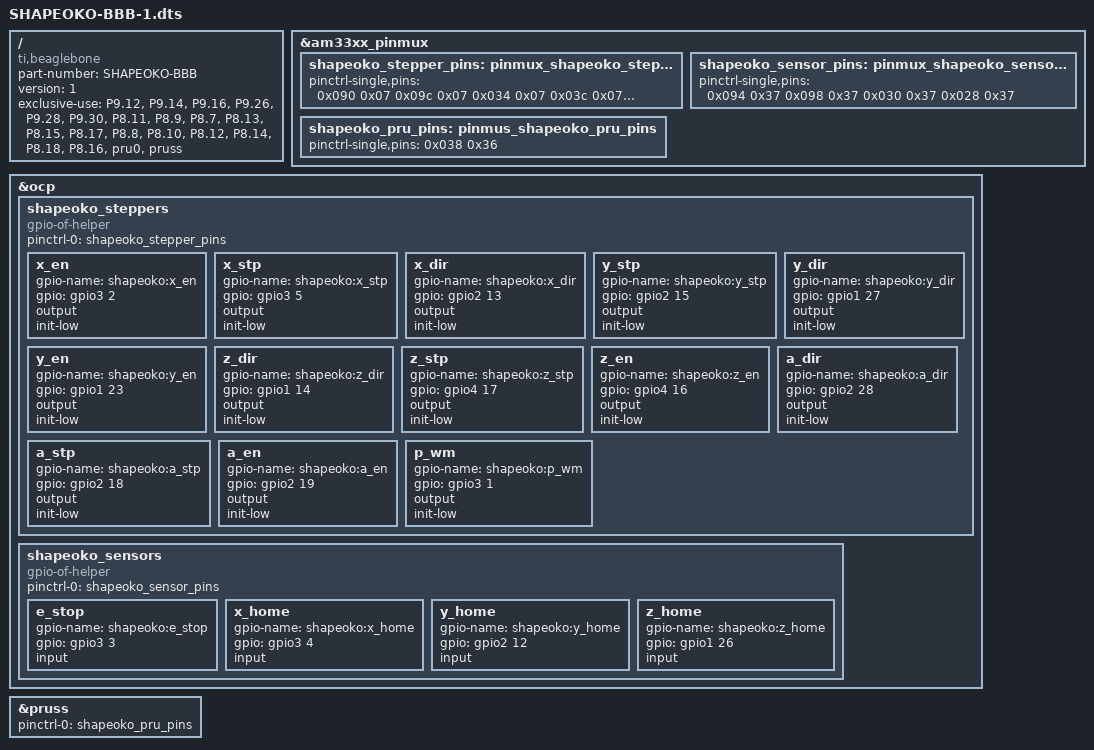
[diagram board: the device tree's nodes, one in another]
// Copyright 2013
// Charles Steinkuehler <charles@steinkuehler.net>
//
// This program is free software; you can redistribute it and/or modify
// it under the terms of the GNU General Public License as published by
// the Free Software Foundation; either version 2 of the License, or
// (at your option) any later version.
//
// This program is distributed in the hope that it will be useful,
// but WITHOUT ANY WARRANTY; without even the implied warranty of
// MERCHANTABILITY or FITNESS FOR A PARTICULAR PURPOSE.  See the
// GNU General Public License for more details.
//
// You should have received a copy of the GNU General Public License
// along with this program; if not, write to the Free Software
// Foundation, Inc., 59 Temple Place, Suite 330, Boston, MA 02111-1307 USA

/dts-v1/;
/plugin/;

/ {
	compatible = "ti,beaglebone", "ti,beaglebone-black";

	/* identification */
	part-number = "SHAPEOKO-BBB";
	version = "1";

	/* state the resources this cape uses */
	exclusive-use =
		/* Steppers */
		"P9.12",  /* gpio 1.28 A-Dir     */
		"P9.14",  /* gpio 1.18 A-Step    */
		"P9.16",  /* gpio 1.19 A-Enable  */
		"P9.26",  /* gpio 0.14 Z-Dir     */
		"P9.28",  /* gpio 3.17 Z-Step    */
		"P9.30",  /* gpio 3.16 Z-Enable  */
		"P8.11",  /* gpio 1.13 X-Dir     */
		"P8.9",   /* gpio 2.5  X-Step    */
		"P8.7",   /* gpio 2.2  X-Enable  */
		"P8.13",  /* gpio 0.23 Y-Dir     */
		"P8.15",  /* gpio 1.15 Y-Step    */
		"P8.17",  /* gpio 0.27 Y-Enable  */

		/* Home sw., E-Stop */
		"P8.8",   /* gpio 2.3  E-Stop    */
		"P8.10",  /* gpio 2.4  X-Home    */
		"P8.12",  /* gpio 1.12 Y-Home    */
		"P8.14",  /* gpio 0.26 Z-Home    */

		/* Spindle + sense */
		"P8.18",  /* gpio 2.1  PWM       */
		"P8.16",  /* gpio 1.14 Sense PRU */

		"pru0",
		"pruss";


	fragment@2 {
		target = <&am33xx_pinmux>;
		__overlay__ {

			shapeoko_stepper_pins: pinmux_shapeoko_stepper_pins {
				status = "okay";
				pinctrl-single,pins = <
					/* stepper outputs (MODE 7, NO receiver, NO pullups, Fast slew) */
					0x090 0x07  /* X-Enable */
					0x09c 0x07  /* X-Step   */
					0x034 0x07  /* X-Dir    */
					0x03c 0x07  /* Y-Step   */
					0x02c 0x07  /* Y-Dir    */
					0x024 0x07  /* Y-Enable */
					0x180 0x07  /* Z-Dir    */
					0x19c 0x07  /* Z-Step   */
					0x198 0x07  /* Z-Enable */
					0x078 0x07  /* A-Dir    */
					0x048 0x07  /* A-Step   */
					0x04c 0x07  /* A-Enable */
					/* Spindle PWM (Mode 7, NO receiver, No pullups, Fast slew) */
					0x08c 0x07  /* PWM      */
				>;
			};
		};
	};

	fragment@3 {
		target = <&ocp>;
		__overlay__ {

			shapeoko_steppers {
				compatible = "gpio-of-helper";
				status = "okay";
				pinctrl-names = "default";
				pinctrl-0 = <&shapeoko_stepper_pins>;

				x_en {
					gpio-name = "shapeoko:x_en";
					gpio = <&gpio3 2 0>;
					output;
					init-low;
				};
				x_stp {
					gpio-name = "shapeoko:x_stp";
					gpio = <&gpio3 5 0>;
					output;
					init-low;
				};
				x_dir {
					gpio-name = "shapeoko:x_dir";
					gpio = <&gpio2 13 0>;
					output;
					init-low;
				};
				y_stp {
					gpio-name = "shapeoko:y_stp";
					gpio = <&gpio2 15 0>;
					output;
					init-low;
				};
				y_dir {
					gpio-name = "shapeoko:y_dir";
					gpio = <&gpio1 27 0>;
					output;
					init-low;
				};
				y_en {
					gpio-name = "shapeoko:y_en";
					gpio = <&gpio1 23 0>;
					output;
					init-low;
				};
				z_dir {
					gpio-name = "shapeoko:z_dir";
					gpio = <&gpio1 14 0>;
					output;
					init-low;
				};
				z_stp {
					gpio-name = "shapeoko:z_stp";
					gpio = <&gpio4 17 0>;
					output;
					init-low;
					};
				z_en {
					gpio-name = "shapeoko:z_en";
					gpio = <&gpio4 16 0>;
					output;
					init-low;
				};
				a_dir {
					gpio-name = "shapeoko:a_dir";
					gpio = <&gpio2 28 0>;
					output;
					init-low;
				};
				a_stp {
					gpio-name = "shapeoko:a_stp";
					gpio = <&gpio2 18 0>;
					output;
					init-low;
				};
				a_en {
					gpio-name = "shapeoko:a_en";
					gpio = <&gpio2 19 0>;
					output;
					init-low;
				};
				p_wm {
					gpio-name = "shapeoko:p_wm";
					gpio = <&gpio3 1 0>;
					output;
					init-low;
				};
			};
		};
	};

	fragment@4 {
		target = <&am33xx_pinmux>;
		 __overlay__ {

			shapeoko_sensor_pins: pinmux_shapeoko_sensor_pins {
				status = "okay";
				pinctrl-single,pins = <
					/* Switch sensors (MODE 7, Receiver, Pullups, Fast slew) */
					0x094 0x37 /* E-Stop */
					0x098 0x37 /* X-Home */
					0x030 0x37 /* Y-Home */
					0x028 0x37 /* Z-Home */
				>;
			};
		};
	};

	fragment@5 {
		target = <&ocp>;
		__overlay__ {

			shapeoko_sensors {
				compatible = "gpio-of-helper";
				status = "okay";
				pinctrl-names = "default";
				pinctrl-0 = <&shapeoko_sensor_pins>;

				e_stop {
					gpio-name = "shapeoko:e_stop";
					gpio = <&gpio3 3 0>;
					input;
				};
				x_home {
					gpio-name = "shapeoko:x_home";
					gpio = <&gpio3 4 0>;
					input;
				};
				y_home {
					gpio-name = "shapeoko:y_home";
					gpio = <&gpio2 12 0>;
					input;
				};
				z_home {
					gpio-name = "shapeoko:z_home";
					gpio = <&gpio1 26 0>;
					input;
				};
			};
		};
	};

	fragment@6 {
		target = <&am33xx_pinmux>;
		__overlay__ {
			shapeoko_pru_pins: pinmus_shapeoko_pru_pins {
				status = "okay";
				pinctrl-single,pins = <
					/* PRU0 direct inputs (MODE 6, Receiver, Pullups, Fast slew) */
					0x038 0x36 /* RPM counter */
				>;
			};
		};
	};

	fragment@7 {
		target = <&pruss>;
		__overlay__ {
			status = "okay";
			pinctrl-names = "default";
			pinctrl-0 = <&shapeoko_pru_pins>;
		};
	};
};
